# Q32M210 register map
File version: 1.0
Registers are 32-bit, read-write, no defined reset value unless marked. A register's access mark holds for its fields unless they carry their own. Offsets are from the block's base; [hi:lo] are bit positions.

## I2C_Interface_Configuration_and_Control
Base 0x40000900
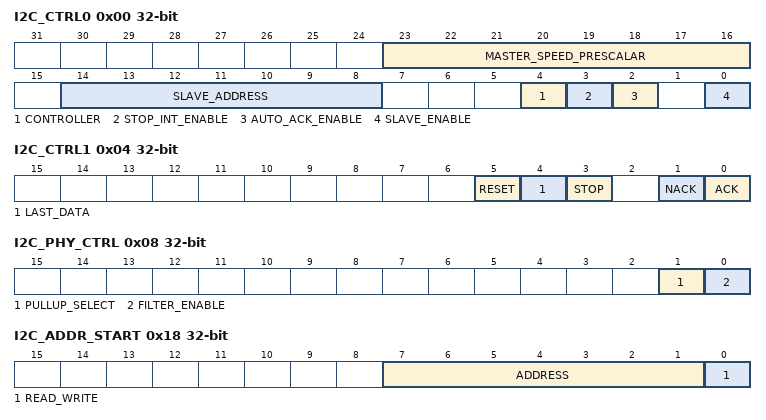
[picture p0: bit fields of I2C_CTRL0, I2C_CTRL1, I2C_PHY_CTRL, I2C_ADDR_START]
0x00 I2C_CTRL0 — I2C Interface Configuration and Control
  [23:16] MASTER_SPEED_PRESCALAR — Prescalar used to convert the interface I2C clock to SCL when operating in I2C interface master mode. I2C clock is prescaled by (MASTER_SPEED_PRESCALAR + 1) * 3
    0=I2C_MASTER_SPEED_3 (Prescale SCL from I2C clock by 3); 1=I2C_MASTER_SPEED_6 (Prescale SCL from I2C clock by 6); 2=I2C_MASTER_SPEED_9 (Prescale SCL from I2C clock by 9); 3=I2C_MASTER_SPEED_12 (Prescale SCL from I2C clock by 12); 4=I2C_MASTER_SPEED_15 (Prescale SCL from I2C clock by 15); 5=I2C_MASTER_SPEED_18 (Prescale SCL from I2C clock by 18); 6=I2C_MASTER_SPEED_21 (Prescale SCL from I2C clock by 21); 7=I2C_MASTER_SPEED_24 (Prescale SCL from I2C clock by 24); 8=I2C_MASTER_SPEED_27 (Prescale SCL from I2C clock by 27); 9=I2C_MASTER_SPEED_30 (Prescale SCL from I2C clock by 30); 10=I2C_MASTER_SPEED_33 (Prescale SCL from I2C clock by 33); 11=I2C_MASTER_SPEED_36 (Prescale SCL from I2C clock by 36); 12=I2C_MASTER_SPEED_39 (Prescale SCL from I2C clock by 39); 13=I2C_MASTER_SPEED_42 (Prescale SCL from I2C clock by 42); 14=I2C_MASTER_SPEED_45 (Prescale SCL from I2C clock by 45); 15=I2C_MASTER_SPEED_48 (Prescale SCL from I2C clock by 48); 16=I2C_MASTER_SPEED_51 (Prescale SCL from I2C clock by 51)
  [14:8] SLAVE_ADDRESS — Set the I2C slave address for this device
  [4] CONTROLLER — Select whether data transfer will be controlled by the ARM Cortex-M3 processor or the DMA for I2C
    0=I2C_CONTROLLER_CM3 (The ARM Cortex-M3 controls data transfers using I2C); 1=I2C_CONTROLLER_DMA (The DMA controls data transfers using I2C)
  [3] STOP_INT_ENABLE — Configure whether stop interrupts will be generated by the I2C interface
    0=I2C_STOP_INT_DISABLE (Stop interrupts will not be generated); 1=I2C_STOP_INT_ENABLE (A stop interrupt will be generated when a stop condition occurs for an active transaction)
  [2] AUTO_ACK_ENABLE — Select whether acknowledgement is automatically generated or not
    0=I2C_AUTO_ACK_DISABLE (Require manual acknowledgement of all I2C interface transfers); 1=I2C_AUTO_ACK_ENABLE (Use automatic acknowledgement for I2C interface transfers)
  [0] SLAVE_ENABLE — Select whether the I2C interface will be enabled for slave mode or not
    0=I2C_SLAVE_DISABLE (Disable I2C interface slave mode operation); 1=I2C_SLAVE_ENABLE (Enable I2C interface slave mode operation)
0x04 I2C_CTRL1 — I2C Interface Status and Control
  [5] RESET — Reset the I2C interface
    1=I2C_RESET (Reset the I2C interface)
  [4] LAST_DATA — Indicate that the current data is the last byte of a data transfer
    1=I2C_LAST_DATA (Indicate that the current data is the last byte of a data transfer)
  [3] STOP — Issue a stop condition on the I2C interface bus
    1=I2C_STOP (Issue a stop condition the I2C interface bus)
  [1] NACK — Issue a not acknowledge on the I2C interface bus
    1=I2C_NACK (Issue a not acknowledge on the I2C interface bus)
  [0] ACK — Issue an acknowledge on the I2C interface bus
    1=I2C_ACK (Issue an acknowledge on the I2C interface bus)
0x08 I2C_PHY_CTRL — I2C Physical Interface Control
  [1] PULLUP_SELECT — Configure the optional pull-up resistors for the I2C interface lines
    0=I2C_PULLUP_1K (Use 1 kohm pull-up resistors on the I2C SCL and SDA lines); 1=I2C_PULLUP_DISABLE (Disconnect the pull-up resistors from the I2C interface)
  [0] FILTER_ENABLE — Configure whether the I2C bus lines will be low-pass filtered
    0=I2C_FILTER_DISABLE (Disable filtering of the I2C bus lines); 1=I2C_FILTER_ENABLE (Enable low-pass filtering of the I2C bus lines)
0x10 I2C_DATA — I2C Interface Data
  [7:0] I2C_DATA — Single byte buffer for data to be transmitted over the I2C interface and data that has been received over the I2C interface
0x14 I2C_DATA_S — I2C Interface Data (Shadow)
  [7:0] I2C_DATA_S — Shadow of the single byte buffer for data to be transmitted over the I2C interface and data that has been received over the I2C interface
0x18 I2C_ADDR_START — I2C Master Address and Start
  [7:1] ADDRESS — I2C address to use for the transaction
  [0] READ_WRITE — Select whether a read or a write transaction is started
    0=I2C_WRITE (Start a I2C write transaction); 1=I2C_READ (Start a I2C read transaction)
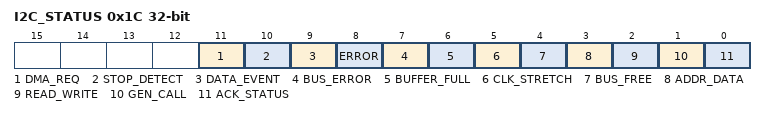
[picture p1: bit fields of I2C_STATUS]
0x1C I2C_STATUS
  [11] DMA_REQ — Indicate if the I2C interface is currently requesting DMA data
    0=I2C_NO_DMA_REQUEST (The I2C interface is not requesting a DMA action); 1=I2C_DMA_REQUEST (The I2C interface is requesting a DMA action)
  [10] STOP_DETECT — Indicate if an I2C stop bit has been detected
    0=I2C_NO_STOP_DETECTED (No stop condition has been detected on the I2C bus); 1=I2C_STOP_DETECTED (A stop condition has been detected on the I2C bus)
  [9] DATA_EVENT — Indicate that the I2C interface either needs data to transmit or has received data
    0=I2C_NON_DATA_EVENT (No I2C data is needed or available); 1=I2C_DATA_EVENT (I2C data is needed or is available)
  [8] ERROR — Indicate if an error has occurred on the I2C interface since this bit was last cleared
    0=I2C_NO_ERROR (An error has not been detected on the I2C bus); 1=I2C_ERROR (An error has been detected on the I2C bus)
  [7] BUS_ERROR — Indicate if the I2C interface state machine indicates a bus error has occurred
    0=I2C_NO_BUS_ERROR (A bus-error has not been detected in the I2C interface state machine); 1=I2C_BUS_ERROR (A bus-error has been detected in the I2C interface state machine)
  [6] BUFFER_FULL — Indicate if the I2C data buffer is full
    0=I2C_BUFFER_EMPTY (The I2C interface buffer is empty); 1=I2C_BUFFER_FULL (The I2C interface buffer is full)
  [5] CLK_STRETCH — Indicate if the I2C interface is holding the clock signal
    0=I2C_CLK_NOT_STRETCHED (The I2C clock line is not being stretched); 1=I2C_CLK_STRETCHED (The I2C SCL line is being held low)
  [4] BUS_FREE — Indicate if the I2C interface bus is free
    0=I2C_BUS_BUSY (One or both of the I2C bus lines is currently 0); 1=I2C_BUS_FREE (Both I2C bus lines are currnently free)
  [3] ADDR_DATA — Indicate if the I2C data register holds an address or data byte
    0=I2C_DATA_IS_DATA (The I2C data register holds data); 1=I2C_DATA_IS_ADDR (The I2C data register holds an address)
  [2] READ_WRITE — Indicate whether the I2C bus transfer is a read or a write
    0=I2C_IS_WRITE (The current I2C transfer is a write); 1=I2C_IS_READ (The current I2C transfer is a read)
  [1] GEN_CALL — Indicate whether the I2C bus transfer is using the general call address or another address
    0=I2C_ADDR_OTHER (The address used for the current I2C transfer is not the general call address); 1=I2C_ADDR_GEN_CALL (The address used for the current I2C transfer is the general call address)
  [0] ACK_STATUS — Indicate whether an acknowledge or a not acknowledge has been received
    0=I2C_HAS_ACK (Indicate that the last I2C byte was acknowledged); 1=I2C_HAS_NACK (Indicate that the last I2C byte was not acknowledged)
